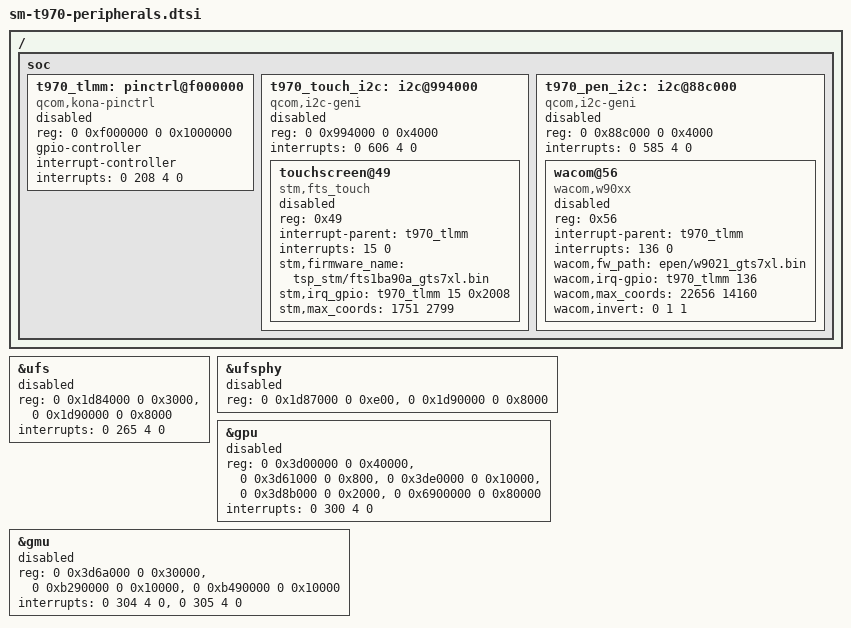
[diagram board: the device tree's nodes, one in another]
// Disabled board resources from the captured SM-T970 stock DT.
// Clocks, regulators, DMA ownership and driver ABI must be wired before enabling.
// The full original declarations remain in evidence/adb-2026-11-01/live-device-tree.dts.

&ufs {
    reg = <0 0x1d84000 0 0x3000>, <0 0x1d90000 0 0x8000>;
    reg-names = "ufs_mem", "ufs_ice";
    interrupts = <0 265 4 0>;
    status = "disabled";
};

&ufsphy {
    reg = <0 0x1d87000 0 0xe00>, <0 0x1d90000 0 0x8000>;
    reg-names = "phy_mem", "ufs_ice";
    status = "disabled";
};

&gpu {
    reg = <0 0x3d00000 0 0x40000>, <0 0x3d61000 0 0x800>, <0 0x3de0000 0 0x10000>, <0 0x3d8b000 0 0x2000>, <0 0x6900000 0 0x80000>;
    reg-names = "kgsl_3d0_reg_memory", "cx_dbgc", "rscc", "isense_cntl", "qdss_gfx";
    interrupts = <0 300 4 0>;
    interrupt-names = "kgsl_3d0_irq";
    // No measured mapping from the stock contexts to a selected DMA driver.
    /delete-property/ iommus;
    status = "disabled";
};

&gmu {
    reg = <0 0x3d6a000 0 0x30000>, <0 0xb290000 0 0x10000>, <0 0xb490000 0 0x10000>;
    reg-names = "kgsl_gmu_reg", "kgsl_gmu_pdc_cfg", "kgsl_gmu_pdc_seq";
    interrupts = <0 304 4 0>, <0 305 4 0>;
    interrupt-names = "kgsl_hfi_irq", "kgsl_gmu_irq";
    // No measured mapping from the stock contexts to a selected DMA driver.
    /delete-property/ iommus;
    status = "disabled";
};

/ {
    soc {
        // GPIO IRQ provider is described but has no selected XNU driver.
        t970_tlmm: pinctrl@f000000 {
            compatible = "qcom,kona-pinctrl";
            reg = <0 0xf000000 0 0x1000000>;
            gpio-controller;
            #gpio-cells = <2>;
            interrupt-controller;
            #interrupt-cells = <2>;
            #address-cells = <0>;
            interrupts = <0 208 4 0>;
            status = "disabled";
        };

        t970_touch_i2c: i2c@994000 {
            compatible = "qcom,i2c-geni";
            reg = <0 0x994000 0 0x4000>;
            interrupts = <0 606 4 0>;
            #address-cells = <1>;
            #size-cells = <0>;
            status = "disabled";
            touchscreen@49 {
                compatible = "stm,fts_touch";
                reg = <0x49>;
                interrupt-parent = <&t970_tlmm>;
                interrupts = <15 0>;
                stm,firmware_name = "tsp_stm/fts1ba90a_gts7xl.bin";
                stm,irq_gpio = <&t970_tlmm 15 0x2008>;
                stm,max_coords = <1751 2799>;
                status = "disabled";
            };
        };

        t970_pen_i2c: i2c@88c000 {
            compatible = "qcom,i2c-geni";
            reg = <0 0x88c000 0 0x4000>;
            interrupts = <0 585 4 0>;
            #address-cells = <1>;
            #size-cells = <0>;
            status = "disabled";
            wacom@56 {
                compatible = "wacom,w90xx";
                reg = <0x56>;
                interrupt-parent = <&t970_tlmm>;
                interrupts = <136 0>;
                wacom,fw_path = "epen/w9021_gts7xl.bin";
                wacom,irq-gpio = <&t970_tlmm 136 0>;
                wacom,max_coords = <22656 14160>;
                wacom,invert = <0 1 1>;
                status = "disabled";
            };
        };

    };
};
